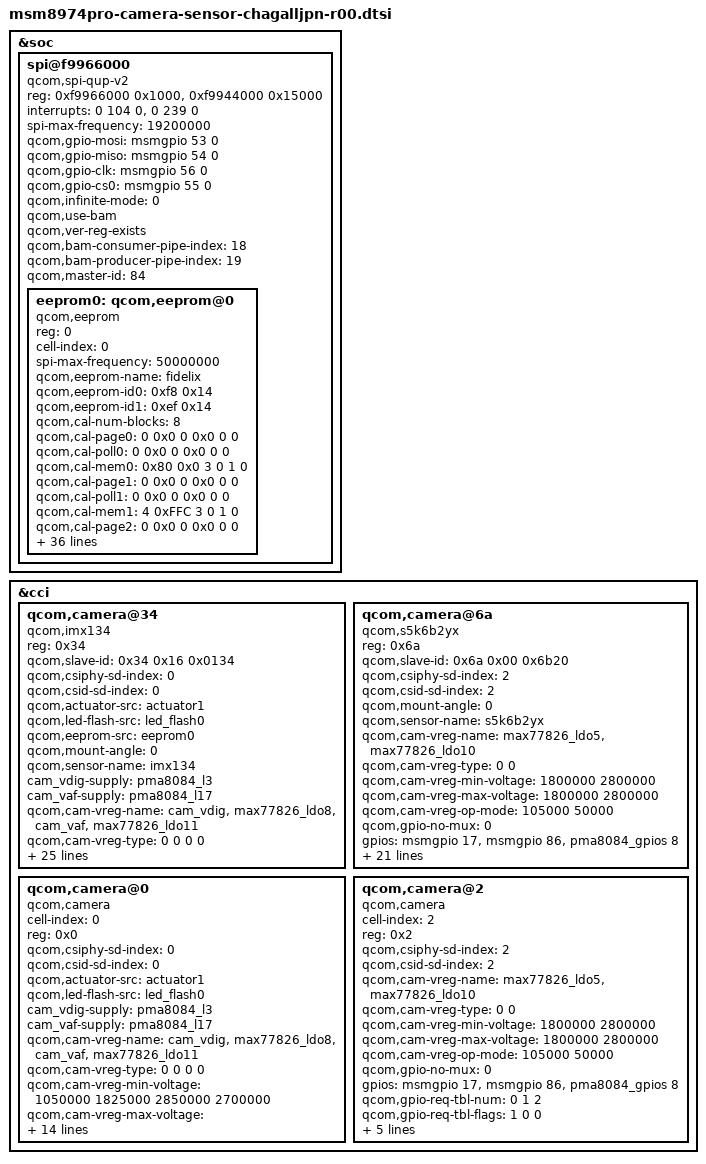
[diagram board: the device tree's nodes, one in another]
/*
 * Copyright (c) 2012-2013, The Linux Foundation. All rights reserved.
 *
 * This program is free software; you can redistribute it and/or modify
 * it under the terms of the GNU General Public License version 2 and
 * only version 2 as published by the Free Software Foundation.
 *
 * This program is distributed in the hope that it will be useful,
 * but WITHOUT ANY WARRANTY; without even the implied warranty of
 * MERCHANTABILITY or FITNESS FOR A PARTICULAR PURPOSE.  See the
 * GNU General Public License for more details.
 */

&soc {

	spi@f9966000 {
                compatible = "qcom,spi-qup-v2";
                #address-cells = <1>;
                #size-cells = <0>;
                reg-names = "spi_physical", "spi_bam_physical";
                reg = <0xf9966000 0x1000>,
                      <0xf9944000 0x15000>;
                interrupt-names = "spi_irq", "spi_bam_irq";
                interrupts = <0 104 0>, <0 239 0>;
                spi-max-frequency = <19200000>;

                qcom,gpio-mosi = <&msmgpio 53 0>;
                qcom,gpio-miso = <&msmgpio 54 0>;
                qcom,gpio-clk  = <&msmgpio 56 0>;
                qcom,gpio-cs0  = <&msmgpio 55 0>;

                qcom,infinite-mode = <0>;
                qcom,use-bam;
                qcom,ver-reg-exists;
                qcom,bam-consumer-pipe-index = <18>;
                qcom,bam-producer-pipe-index = <19>;
                qcom,master-id = <84>;
		status = "ok";

		eeprom0: qcom,eeprom@0 {
			compatible = "qcom,eeprom";
			reg = <0>;
			cell-index = <0>;
			spi-max-frequency = <50000000>;
			qcom,eeprom-name = "fidelix";
			qcom,eeprom-id0 = <0xf8 0x14>;
			qcom,eeprom-id1 = <0xef 0x14>;

			qcom,cal-num-blocks = <8>;
			qcom,cal-page0 = <0 0x0 0 0x0 0 0>;
			qcom,cal-poll0 = <0 0x0 0 0x0 0 0>;
			qcom,cal-mem0 = <0x80 0x0 3 0 1 0>;
			qcom,cal-page1 = <0 0x0 0 0x0 0 0>;
			qcom,cal-poll1 = <0 0x0 0 0x0 0 0>;
			qcom,cal-mem1 = <4 0xFFC 3 0 1 0>;
			qcom,cal-page2 = <0 0x0 0 0x0 0 0>;
			qcom,cal-poll2 = <0 0x0 0 0x0 0 0>;
			qcom,cal-mem2 = <0x900 0x1000 3 0 1 0>;
			qcom,cal-page3 = <0 0x0 0 0x0 0 0>;
			qcom,cal-poll3 = <0 0x0 0 0x0 0 0>;
			qcom,cal-mem3 = <4 0x1FFC 3 0 1 0>;
			qcom,cal-page4 = <0 0x0 0 0x0 0 0>;
			qcom,cal-poll4 = <0 0x0 0 0x0 0 0>;
			qcom,cal-mem4 = <0x40 0x2000 3 0 1 0>;
			qcom,cal-page5 = <0 0x0 0 0x0 0 0>;
			qcom,cal-poll5 = <0 0x0 0 0x0 0 0>;
			qcom,cal-mem5 = <4 0x2FFC 3 0 1 0>;
			qcom,cal-page6 = <0 0x0 0 0x0 0 0>;
			qcom,cal-poll6 = <0 0x0 0 0x0 0 0>;
			qcom,cal-mem6 = <0x700 0x3000 3 0 1 0>;
			qcom,cal-page7 = <0 0x0 0 0x0 0 0>;
			qcom,cal-poll7 = <0 0x0 0 0x0 0 0>;
			qcom,cal-mem7 = <4 0x3FFC 3 0 1 0>;


			qcom,cam-vreg-name = "max77826_ldo8";
			qcom,cam-vreg-type = <0>;
			qcom,camvreg-min-voltage = <1800000>;
			qcom,cam-vreg-max-voltage = <1800000>;
			qcom,cam-vreg-op-mode = <5000>;
			qcom,cam-power-seq-type = "sensor_vreg";
			qcom,cam-power-seq-val = "max77826_ldo8";
			qcom,cam-power-seq-cfg-val = <1>;
			qcom,cam-power-seq-delay = <1>;

			qcom,spiop-read = <0x03 3 0 0 0>;
			qcom,spiop-readseq = <0x03 3 0 0 0>;
			qcom,spiop-queryid = <0x90 3 0 0 0>;
			qcom,spiop-pprog = <0x02 3 0 3 3>;
			qcom,spiop-wenable = <0x06 0 0 0 0>;
			qcom,spiop-readst = <0x05 0 0 0 0>;
			qcom,spiop-erase = <0x20 3 0 10 30>;
			qcom,spi-busy-mask = <0x01>;
			qcom,spi-page-size = <256>;
			qcom,spi-erase-size = <4096>;
		};
	};
};

&cci {

    qcom,camera@34 {
		compatible = "qcom,imx134";
		reg = <0x34>;
		qcom,slave-id = <0x34 0x16 0x0134>;
		qcom,csiphy-sd-index = <0>;
		qcom,csid-sd-index = <0>;
		qcom,actuator-src = <&actuator1>;
		qcom,led-flash-src = <&led_flash0>;
		qcom,eeprom-src = <&eeprom0>;
		qcom,mount-angle = <0>;
		qcom,sensor-name = "imx134";
		cam_vdig-supply = <&pma8084_l3>;
		cam_vaf-supply = <&pma8084_l17>;
		qcom,cam-vreg-name = "cam_vdig", "max77826_ldo8", "cam_vaf", "max77826_ldo11";
		qcom,cam-vreg-type = <0 0 0 0>;
		qcom,cam-vreg-min-voltage = <1050000 1825000 2850000 2700000>;
		qcom,cam-vreg-max-voltage = <1050000 1825000 2850000 2700000>;
		qcom,cam-vreg-op-mode = <105000 105000 100000 50000>;
		qcom,gpio-no-mux = <0>;
		gpios = <&msmgpio 15 0>,
			<&pma8084_gpios 18 0>,
			<&pma8084_mpps 7 0>,
			<&pma8084_gpios 13 0>;
		qcom,gpio-reset = <1>;
		qcom,gpio-ext-torch-en = <2>;
		qcom,gpio-ext-flash-en = <3>;
		qcom,gpio-req-tbl-num = <0 1>;
		qcom,gpio-req-tbl-flags = <1 0>;
		qcom,gpio-req-tbl-label = "CAMIF_MCLK", "CAM_RESET1";
		qcom,gpio-set-tbl-num = <1 1>;
		qcom,gpio-set-tbl-flags = <0 2>;
		qcom,gpio-set-tbl-delay = <1000 30000>;
		qcom,csi-lane-assign = <0x4320>;
		qcom,csi-lane-mask = <0x1F>;
		qcom,sensor-position = <0>;
		qcom,sensor-mode = <0>;
	        qcom,sensor-type = <0>;
		qcom,cci-master = <0>;
		status = "ok";
	};

	qcom,camera@6a {
		compatible = "qcom,s5k6b2yx";
		reg = <0x6a>;
		qcom,slave-id = <0x6a 0x00 0x6b20>;
		qcom,csiphy-sd-index = <2>;
		qcom,csid-sd-index = <2>;
		qcom,mount-angle = <0>;
		qcom,sensor-name = "s5k6b2yx";
		qcom,cam-vreg-name = "max77826_ldo5", "max77826_ldo10";
		qcom,cam-vreg-type = <0 0>;
		qcom,cam-vreg-min-voltage = <1800000 2800000>;
		qcom,cam-vreg-max-voltage = <1800000 2800000>;
		qcom,cam-vreg-op-mode = <105000 50000>;
		qcom,gpio-no-mux = <0>;
		gpios = <&msmgpio 17 0>,
		        <&msmgpio 86 0>,
		        <&pma8084_gpios 8 0>;
		qcom,gpio-req-tbl-num = <0 1 2>;
		qcom,gpio-req-tbl-flags = <1 0 0>;
		qcom,gpio-req-tbl-label = "CAMIF_MCLK",
					  "CAM_RESET1",
					  "CAM_STBY";
		qcom,gpio-reset = <1>;
		qcom,gpio-standby = <2>;
		qcom,cam-power-seq-type = "sensor_vreg",
					  "sensor_vreg",
					  "sensor_gpio",
					  "sensor_gpio",
					  "sensor_gpio",
					  "sensor_clk",
					  "sensor_i2c_mux";
		qcom,cam-power-seq-val = "max77826_ldo5",
					 "max77826_ldo10",
					 "sensor_gpio_reset",
					 "sensor_gpio_standby",
					 "sensor_gpio_reset",
					 "sensor_cam_mclk",
					 "none";
		qcom,cam-power-seq-cfg-val = <1 1 0 0 1 0 0>;
		qcom,cam-power-seq-delay = <1 1 1 1 2 1 0>;
		qcom,csi-lane-assign = <0x4320>;
		qcom,csi-lane-mask = <0x3>;
		qcom,sensor-position = <1>;
		qcom,sensor-mode = <1>;
		qcom,sensor-type = <0>;
		qcom,cci-master = <1>;
		status = "ok";
	};

	qcom,camera@0 {
		cell-index = <0>;
		compatible = "qcom,camera";
		reg = <0x0>;
		qcom,csiphy-sd-index = <0>;
		qcom,csid-sd-index = <0>;
		qcom,actuator-src = <&actuator1>;
		qcom,led-flash-src = <&led_flash0>;
		cam_vdig-supply = <&pma8084_l3>;
		cam_vaf-supply = <&pma8084_l17>;
		qcom,cam-vreg-name = "cam_vdig", "max77826_ldo8", "cam_vaf", "max77826_ldo11";
		qcom,cam-vreg-type = <0 0 0 0>;
		qcom,cam-vreg-min-voltage = <1050000 1825000 2850000 2700000>;
		qcom,cam-vreg-max-voltage = <1050000 1825000 2850000 2700000>;
		qcom,cam-vreg-op-mode = <105000 105000 100000 50000>;
		qcom,gpio-no-mux = <0>;
		gpios = <&msmgpio 15 0>,
			<&pma8084_gpios 18 0>,
			<&pma8084_mpps 7 0>,
			<&pma8084_gpios 13 0>;
		qcom,gpio-reset = <1>;
		qcom,gpio-ext-torch-en = <2>;
		qcom,gpio-ext-flash-en = <3>;
		qcom,gpio-req-tbl-num = <0 1>;
		qcom,gpio-req-tbl-flags = <1 0>;
		qcom,gpio-req-tbl-label = "CAMIF_MCLK", "CAM_RESET1";
		qcom,cci-master = <0>;
		status = "ok";
	};

	qcom,camera@2 {
		cell-index = <2>;
		compatible = "qcom,camera";
		reg = <0x2>;
		qcom,csiphy-sd-index = <2>;
		qcom,csid-sd-index = <2>;
		qcom,cam-vreg-name = "max77826_ldo5", "max77826_ldo10";
		qcom,cam-vreg-type = <0 0>;
		qcom,cam-vreg-min-voltage = <1800000 2800000>;
		qcom,cam-vreg-max-voltage = <1800000 2800000>;
		qcom,cam-vreg-op-mode = <105000 50000>;
		qcom,gpio-no-mux = <0>;
		gpios = <&msmgpio 17 0>,
		        <&msmgpio 86 0>,
		        <&pma8084_gpios 8 0>;
		qcom,gpio-req-tbl-num = <0 1 2>;
		qcom,gpio-req-tbl-flags = <1 0 0>;
		qcom,gpio-req-tbl-label = "CAMIF_MCLK",
					  "CAM_RESET1",
					  "CAM_STBY";
		qcom,gpio-reset = <1>;
		qcom,gpio-standby = <2>;

		qcom,cci-master = <1>;
		status = "ok";
	};
};
